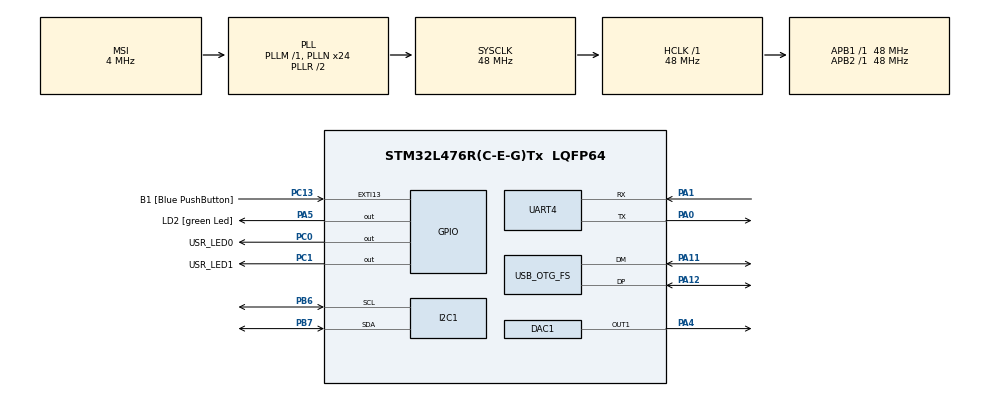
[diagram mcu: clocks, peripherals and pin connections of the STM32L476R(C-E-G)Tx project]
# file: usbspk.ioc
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DAC1.DAC_Trigger-DAC_OUT1=DAC_TRIGGER_SOFTWARE
DAC1.WaveGeneration-DAC_OUT1=DISABLE
I2C1.Timing=0x20303E5D
Mcu.Family=STM32L4
Mcu.Name=STM32L476R(C-E-G)Tx
Mcu.Package=LQFP64
NVIC.OTG_FS_IRQn=true\:0\:0\:false\:false\:true
NVIC.PriorityGroup=NVIC_PRIORITYGROUP_4
NVIC.TIM6_DAC_IRQn=true\:0\:0\:false\:false\:true
NVIC.TIM7_IRQn=true\:0\:0\:false\:false\:true
PA0.Mode=Asynchronous
PA0.Signal=UART4_TX
PA1.Mode=Asynchronous
PA1.Signal=UART4_RX
PA11.Mode=Device_Only
PA11.Signal=USB_OTG_FS_DM
PA12.Mode=Device_Only
PA12.Signal=USB_OTG_FS_DP
PA13\ (JTMS-SWDIO).GPIO_Label=TMS
PA13\ (JTMS-SWDIO).Signal=SYS_JTMS-SWDIO
PA14\ (JTCK-SWCLK).GPIO_Label=TCK
PA14\ (JTCK-SWCLK).Signal=SYS_JTCK-SWCLK
PA2.GPIO_Label=USART_TX
PA2.GPIO_Mode=GPIO_MODE_AF_PP
PA2.GPIO_PuPd=GPIO_NOPULL
PA2.GPIO_Speed=GPIO_SPEED_FREQ_VERY_HIGH
PA2.Signal=USART2_TX
PA3.GPIO_Label=USART_RX
PA3.GPIO_Mode=GPIO_MODE_AF_PP
PA3.GPIO_PuPd=GPIO_NOPULL
PA3.GPIO_Speed=GPIO_SPEED_FREQ_VERY_HIGH
PA3.Signal=USART2_RX
PA4.Signal=COMP_DAC11_group
PA5.GPIO_Label=LD2 [green Led]
PA5.GPIO_ModeDefaultOutputPP=GPIO_MODE_OUTPUT_PP
PA5.GPIO_PuPd=GPIO_NOPULL
PA5.GPIO_Speed=GPIO_SPEED_FREQ_LOW
PA5.Signal=GPIO_Output
PB3\ (JTDO-TRACESWO).GPIO_Label=SWO
PB3\ (JTDO-TRACESWO).Signal=SYS_JTDO-SWO
PB6.Mode=I2C
PB6.Signal=I2C1_SCL
PB7.Mode=I2C
PB7.Signal=I2C1_SDA
PC0.GPIO_Label=USR_LED0
PC0.Signal=GPIO_Output
PC1.GPIO_Label=USR_LED1
PC1.Signal=GPIO_Output
PC13.GPIO_Label=B1 [Blue PushButton]
PC13.GPIO_ModeDefaultEXTI=GPIO_MODE_IT_FALLING
PC13.GPIO_PuPd=GPIO_NOPULL
PC13.Signal=GPXTI13
PC14-OSC32_IN\ (PC14).Signal=RCC_OSC32_IN
PC15-OSC32_OUT\ (PC15).Signal=RCC_OSC32_OUT
PH0-OSC_IN\ (PH0).Signal=RCC_OSC_IN
PH1-OSC_OUT\ (PH1).Signal=RCC_OSC_OUT
ProjectManager.HeapSize=0x200
ProjectManager.StackSize=0x400
ProjectManager.TargetToolchain=Makefile
RCC.ADCFreq_Value=48000000
RCC.AHBFreq_Value=48000000
RCC.APB1Freq_Value=48000000
RCC.APB1TimFreq_Value=48000000
RCC.APB2Freq_Value=48000000
RCC.APB2TimFreq_Value=48000000
RCC.CortexFreq_Value=48000000
RCC.HCLKFreq_Value=48000000
RCC.HSE_VALUE=8000000
RCC.HSI_VALUE=16000000
RCC.LSE_VALUE=32768
RCC.MSI_VALUE=4000000
RCC.PLLN=24
RCC.PLLSAI1N=24
RCC.PREFETCH_ENABLE=1
RCC.SYSCLKFreq_VALUE=48000000
RCC.SYSCLKSource=RCC_SYSCLKSOURCE_PLLCLK
RCC.USBFreq_Value=48000000
RCC.VCOOutputFreq_Value=96000000
SH.COMP_DAC11_group.0=DAC1_OUT1,DAC_OUT1
TIM7.Period=1000
TIM7.TIM_MasterOutputTrigger=TIM_TRGO_UPDATE
UART4.WordLength=WORDLENGTH_8B
USB_DEVICE.CLASS_NAME_FS=AUDIO
USB_DEVICE.USBD_AUDIO_FREQ=24000
USB_DEVICE.VirtualMode=Audio
USB_DEVICE.VirtualModeFS=Audio_FS
USB_OTG_FS.VirtualMode=Device_Only
USB_OTG_FS.vbus_sensing_enable=DISABLE
VP_TIM7_VS_ClockSourceINT.Mode=Enable_Timer
VP_USB_DEVICE_VS_USB_DEVICE_AUDIO_FS.Mode=AUDIO_FS
board=NUCLEO-L476RG

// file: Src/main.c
/**
  ******************************************************************************
  * File Name          : main.c
  * Description        : Main program body
  ******************************************************************************
  * This notice applies to any and all portions of this file
  * that are not between comment pairs USER CODE BEGIN and
  * USER CODE END. Other portions of this file, whether
  * inserted by the user or by software development tools
  * are owned by their respective copyright owners.
  *
  * Copyright (c) 2017 STMicroelectronics International N.V.
  * All rights reserved.
  *
  * Redistribution and use in source and binary forms, with or without
  * modification, are permitted, provided that the following conditions are met:
  *
  * 1. Redistribution of source code must retain the above copyright notice,
  *    this list of conditions and the following disclaimer.
  * 2. Redistributions in binary form must reproduce the above copyright notice,
  *    this list of conditions and the following disclaimer in the documentation
  *    and/or other materials provided with the distribution.
  * 3. Neither the name of STMicroelectronics nor the names of other
  *    contributors to this software may be used to endorse or promote products
  *    derived from this software without specific written permission.
  * 4. This software, including modifications and/or derivative works of this
  *    software, must execute solely and exclusively on microcontroller or
  *    microprocessor devices manufactured by or for STMicroelectronics.
  * 5. Redistribution and use of this software other than as permitted under
  *    this license is void and will automatically terminate your rights under
  *    this license.
  *
  * THIS SOFTWARE IS PROVIDED BY STMICROELECTRONICS AND CONTRIBUTORS "AS IS"
  * AND ANY EXPRESS, IMPLIED OR STATUTORY WARRANTIES, INCLUDING, BUT NOT
  * LIMITED TO, THE IMPLIED WARRANTIES OF MERCHANTABILITY, FITNESS FOR A
  * PARTICULAR PURPOSE AND NON-INFRINGEMENT OF THIRD PARTY INTELLECTUAL PROPERTY
  * RIGHTS ARE DISCLAIMED TO THE FULLEST EXTENT PERMITTED BY LAW. IN NO EVENT
  * SHALL STMICROELECTRONICS OR CONTRIBUTORS BE LIABLE FOR ANY DIRECT, INDIRECT,
  * INCIDENTAL, SPECIAL, EXEMPLARY, OR CONSEQUENTIAL DAMAGES (INCLUDING, BUT NOT
  * LIMITED TO, PROCUREMENT OF SUBSTITUTE GOODS OR SERVICES; LOSS OF USE, DATA,
  * OR PROFITS; OR BUSINESS INTERRUPTION) HOWEVER CAUSED AND ON ANY THEORY OF
  * LIABILITY, WHETHER IN CONTRACT, STRICT LIABILITY, OR TORT (INCLUDING
  * NEGLIGENCE OR OTHERWISE) ARISING IN ANY WAY OUT OF THE USE OF THIS SOFTWARE,
  * EVEN IF ADVISED OF THE POSSIBILITY OF SUCH DAMAGE.
  *
  ******************************************************************************
  */
#include "main.h"
#include "stm32l4xx_hal.h"
#include "usb_device.h"

/* USER CODE BEGIN Includes */
#include "board.h"

/* USER CODE END Includes */

DAC_HandleTypeDef hdac1;

I2C_HandleTypeDef hi2c1;

TIM_HandleTypeDef htim7;

UART_HandleTypeDef huart4;

/* USER CODE BEGIN PV */
/* Private variables ---------------------------------------------------------*/

/* USER CODE END PV */

void SystemClock_Config(void);
static void MX_GPIO_Init(void);
static void MX_UART4_Init(void);
static void MX_I2C1_Init(void);
static void MX_DAC1_Init(void);
static void MX_TIM7_Init(void);

/* USER CODE BEGIN PFP */
/* Private function prototypes -----------------------------------------------*/

/* USER CODE END PFP */

int main(void)
{

  /* MCU Configuration----------------------------------------------------------*/

  /* Reset of all peripherals, Initializes the Flash interface and the Systick. */
  HAL_Init();

  /* Configure the system clock */
  SystemClock_Config();

  /* Initialize all configured peripherals */
  MX_GPIO_Init();
  MX_UART4_Init();
  MX_USB_DEVICE_Init();
  MX_I2C1_Init();
  MX_DAC1_Init();
  MX_TIM7_Init();

  /* USER CODE BEGIN 2 */
	UART_Printf("USB Speaker Demo\r\n");

  /* USER CODE END 2 */

  /* Infinite loop */
	while (1)
	{

	}

}

/** System Clock Configuration
*/
void SystemClock_Config(void)
{

  RCC_OscInitTypeDef RCC_OscInitStruct;
  RCC_ClkInitTypeDef RCC_ClkInitStruct;
  RCC_PeriphCLKInitTypeDef PeriphClkInit;

    /**Initializes the CPU, AHB and APB busses clocks
    */
  RCC_OscInitStruct.OscillatorType = RCC_OSCILLATORTYPE_MSI;
  RCC_OscInitStruct.MSIState = RCC_MSI_ON;
  RCC_OscInitStruct.MSICalibrationValue = 0;
  RCC_OscInitStruct.MSIClockRange = RCC_MSIRANGE_6;
  RCC_OscInitStruct.PLL.PLLState = RCC_PLL_ON;
  RCC_OscInitStruct.PLL.PLLSource = RCC_PLLSOURCE_MSI;
  RCC_OscInitStruct.PLL.PLLM = 1;
  RCC_OscInitStruct.PLL.PLLN = 24;
  RCC_OscInitStruct.PLL.PLLP = RCC_PLLP_DIV7;
  RCC_OscInitStruct.PLL.PLLQ = RCC_PLLQ_DIV2;
  RCC_OscInitStruct.PLL.PLLR = RCC_PLLR_DIV2;
  if (HAL_RCC_OscConfig(&RCC_OscInitStruct) != HAL_OK)
  {
    _Error_Handler(__FILE__, __LINE__);
  }

    /**Initializes the CPU, AHB and APB busses clocks
    */
  RCC_ClkInitStruct.ClockType = RCC_CLOCKTYPE_HCLK|RCC_CLOCKTYPE_SYSCLK
                              |RCC_CLOCKTYPE_PCLK1|RCC_CLOCKTYPE_PCLK2;
  RCC_ClkInitStruct.SYSCLKSource = RCC_SYSCLKSOURCE_PLLCLK;
  RCC_ClkInitStruct.AHBCLKDivider = RCC_SYSCLK_DIV1;
  RCC_ClkInitStruct.APB1CLKDivider = RCC_HCLK_DIV1;
  RCC_ClkInitStruct.APB2CLKDivider = RCC_HCLK_DIV1;

  if (HAL_RCC_ClockConfig(&RCC_ClkInitStruct, FLASH_LATENCY_2) != HAL_OK)
  {
    _Error_Handler(__FILE__, __LINE__);
  }

  PeriphClkInit.PeriphClockSelection = RCC_PERIPHCLK_UART4|RCC_PERIPHCLK_I2C1
                              |RCC_PERIPHCLK_USB;
  PeriphClkInit.Uart4ClockSelection = RCC_UART4CLKSOURCE_PCLK1;
  PeriphClkInit.I2c1ClockSelection = RCC_I2C1CLKSOURCE_PCLK1;
  PeriphClkInit.UsbClockSelection = RCC_USBCLKSOURCE_PLLSAI1;
  PeriphClkInit.PLLSAI1.PLLSAI1Source = RCC_PLLSOURCE_MSI;
  PeriphClkInit.PLLSAI1.PLLSAI1M = 1;
  PeriphClkInit.PLLSAI1.PLLSAI1N = 24;
  PeriphClkInit.PLLSAI1.PLLSAI1P = RCC_PLLP_DIV7;
  PeriphClkInit.PLLSAI1.PLLSAI1Q = RCC_PLLQ_DIV2;
  PeriphClkInit.PLLSAI1.PLLSAI1R = RCC_PLLR_DIV2;
  PeriphClkInit.PLLSAI1.PLLSAI1ClockOut = RCC_PLLSAI1_48M2CLK;
  if (HAL_RCCEx_PeriphCLKConfig(&PeriphClkInit) != HAL_OK)
  {
    _Error_Handler(__FILE__, __LINE__);
  }

    /**Configure the main internal regulator output voltage
    */
  if (HAL_PWREx_ControlVoltageScaling(PWR_REGULATOR_VOLTAGE_SCALE1) != HAL_OK)
  {
    _Error_Handler(__FILE__, __LINE__);
  }

    /**Configure the Systick interrupt time
    */
  HAL_SYSTICK_Config(HAL_RCC_GetHCLKFreq()/1000);

    /**Configure the Systick
    */
  HAL_SYSTICK_CLKSourceConfig(SYSTICK_CLKSOURCE_HCLK);

  /* SysTick_IRQn interrupt configuration */
  HAL_NVIC_SetPriority(SysTick_IRQn, 0, 0);
}

/* DAC1 init function */
static void MX_DAC1_Init(void)
{

  DAC_ChannelConfTypeDef sConfig;

    /**DAC Initialization
    */
  hdac1.Instance = DAC1;
  if (HAL_DAC_Init(&hdac1) != HAL_OK)
  {
    _Error_Handler(__FILE__, __LINE__);
  }

    /**DAC channel OUT1 config
    */
  sConfig.DAC_SampleAndHold = DAC_SAMPLEANDHOLD_DISABLE;
  sConfig.DAC_Trigger = DAC_TRIGGER_SOFTWARE;
  sConfig.DAC_OutputBuffer = DAC_OUTPUTBUFFER_ENABLE;
  sConfig.DAC_ConnectOnChipPeripheral = DAC_CHIPCONNECT_DISABLE;
  sConfig.DAC_UserTrimming = DAC_TRIMMING_FACTORY;
  if (HAL_DAC_ConfigChannel(&hdac1, &sConfig, DAC_CHANNEL_1) != HAL_OK)
  {
    _Error_Handler(__FILE__, __LINE__);
  }

}

/* I2C1 init function */
static void MX_I2C1_Init(void)
{

  hi2c1.Instance = I2C1;
  hi2c1.Init.Timing = 0x20303E5D;
  hi2c1.Init.OwnAddress1 = 0;
  hi2c1.Init.AddressingMode = I2C_ADDRESSINGMODE_7BIT;
  hi2c1.Init.DualAddressMode = I2C_DUALADDRESS_DISABLE;
  hi2c1.Init.OwnAddress2 = 0;
  hi2c1.Init.OwnAddress2Masks = I2C_OA2_NOMASK;
  hi2c1.Init.GeneralCallMode = I2C_GENERALCALL_DISABLE;
  hi2c1.Init.NoStretchMode = I2C_NOSTRETCH_DISABLE;
  if (HAL_I2C_Init(&hi2c1) != HAL_OK)
  {
    _Error_Handler(__FILE__, __LINE__);
  }

    /**Configure Analogue filter
    */
  if (HAL_I2CEx_ConfigAnalogFilter(&hi2c1, I2C_ANALOGFILTER_ENABLE) != HAL_OK)
  {
    _Error_Handler(__FILE__, __LINE__);
  }

    /**Configure Digital filter
    */
  if (HAL_I2CEx_ConfigDigitalFilter(&hi2c1, 0) != HAL_OK)
  {
    _Error_Handler(__FILE__, __LINE__);
  }

}

/* TIM7 init function */
static void MX_TIM7_Init(void)
{

  TIM_MasterConfigTypeDef sMasterConfig;

  htim7.Instance = TIM7;
  htim7.Init.Prescaler = 0;
  htim7.Init.CounterMode = TIM_COUNTERMODE_UP;
  htim7.Init.Period = 1000;
  if (HAL_TIM_Base_Init(&htim7) != HAL_OK)
  {
    _Error_Handler(__FILE__, __LINE__);
  }

  sMasterConfig.MasterOutputTrigger = TIM_TRGO_UPDATE;
  sMasterConfig.MasterSlaveMode = TIM_MASTERSLAVEMODE_DISABLE;
  if (HAL_TIMEx_MasterConfigSynchronization(&htim7, &sMasterConfig) != HAL_OK)
  {
    _Error_Handler(__FILE__, __LINE__);
  }

}

/* UART4 init function */
static void MX_UART4_Init(void)
{

  huart4.Instance = UART4;
  huart4.Init.BaudRate = 115200;
  huart4.Init.WordLength = UART_WORDLENGTH_8B;
  huart4.Init.StopBits = UART_STOPBITS_1;
  huart4.Init.Parity = UART_PARITY_NONE;
  huart4.Init.Mode = UART_MODE_TX_RX;
  huart4.Init.HwFlowCtl = UART_HWCONTROL_NONE;
  huart4.Init.OverSampling = UART_OVERSAMPLING_16;
  huart4.Init.OneBitSampling = UART_ONE_BIT_SAMPLE_DISABLE;
  huart4.AdvancedInit.AdvFeatureInit = UART_ADVFEATURE_NO_INIT;
  if (HAL_UART_Init(&huart4) != HAL_OK)
  {
    _Error_Handler(__FILE__, __LINE__);
  }

}

/** Configure pins as
        * Analog
        * Input
        * Output
        * EVENT_OUT
        * EXTI
     PA2   ------> USART2_TX
     PA3   ------> USART2_RX
*/
static void MX_GPIO_Init(void)
{

  GPIO_InitTypeDef GPIO_InitStruct;

  /* GPIO Ports Clock Enable */
  __HAL_RCC_GPIOC_CLK_ENABLE();
  __HAL_RCC_GPIOH_CLK_ENABLE();
  __HAL_RCC_GPIOA_CLK_ENABLE();
  __HAL_RCC_GPIOB_CLK_ENABLE();

  /*Configure GPIO pin Output Level */
  HAL_GPIO_WritePin(GPIOC, USR_LED0_Pin|USR_LED1_Pin, GPIO_PIN_RESET);

  /*Configure GPIO pin Output Level */
  HAL_GPIO_WritePin(LD2_GPIO_Port, LD2_Pin, GPIO_PIN_RESET);

  /*Configure GPIO pin : B1_Pin */
  GPIO_InitStruct.Pin = B1_Pin;
  GPIO_InitStruct.Mode = GPIO_MODE_IT_FALLING;
  GPIO_InitStruct.Pull = GPIO_NOPULL;
  HAL_GPIO_Init(B1_GPIO_Port, &GPIO_InitStruct);

  /*Configure GPIO pins : USR_LED0_Pin USR_LED1_Pin */
  GPIO_InitStruct.Pin = USR_LED0_Pin|USR_LED1_Pin;
  GPIO_InitStruct.Mode = GPIO_MODE_OUTPUT_PP;
  GPIO_InitStruct.Pull = GPIO_NOPULL;
  GPIO_InitStruct.Speed = GPIO_SPEED_FREQ_LOW;
  HAL_GPIO_Init(GPIOC, &GPIO_InitStruct);

  /*Configure GPIO pins : USART_TX_Pin USART_RX_Pin */
  GPIO_InitStruct.Pin = USART_TX_Pin|USART_RX_Pin;
  GPIO_InitStruct.Mode = GPIO_MODE_AF_PP;
  GPIO_InitStruct.Pull = GPIO_NOPULL;
  GPIO_InitStruct.Speed = GPIO_SPEED_FREQ_VERY_HIGH;
  GPIO_InitStruct.Alternate = GPIO_AF7_USART2;
  HAL_GPIO_Init(GPIOA, &GPIO_InitStruct);

  /*Configure GPIO pin : LD2_Pin */
  GPIO_InitStruct.Pin = LD2_Pin;
  GPIO_InitStruct.Mode = GPIO_MODE_OUTPUT_PP;
  GPIO_InitStruct.Pull = GPIO_NOPULL;
  GPIO_InitStruct.Speed = GPIO_SPEED_FREQ_LOW;
  HAL_GPIO_Init(LD2_GPIO_Port, &GPIO_InitStruct);

}

void _Error_Handler(char * file, int line)
{
  /* USER CODE BEGIN Error_Handler_Debug */
	/* User can add his own implementation to report the HAL error return state */
	UART_Printf("_Error_Handler: %s, %d", file, line);
	while(1)
	{
	}
  /* USER CODE END Error_Handler_Debug */
}

#ifdef USE_FULL_ASSERT

/**
   * @brief Reports the name of the source file and the source line number
   * where the assert_param error has occurred.
   * @param file: pointer to the source file name
   * @param line: assert_param error line source number
   * @retval None
   */
void assert_failed(uint8_t* file, uint32_t line)
{
  /* USER CODE BEGIN 6 */
	/* User can add his own implementation to report the file name and line number,
	  ex: printf("Wrong parameters value: file %s on line %d\r\n", file, line) */
	UART_Printf("_Error_Handler: %s, %d", file, line);
  /* USER CODE END 6 */

}

#endif

/************************ (C) COPYRIGHT STMicroelectronics *****END OF FILE****/
